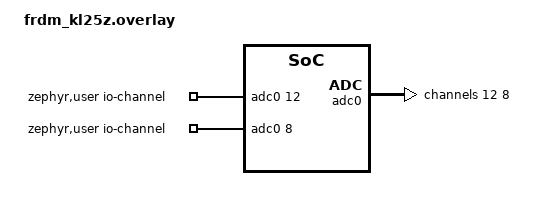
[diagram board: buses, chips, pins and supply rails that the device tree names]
&gpiod {
status = "okay";
};
/ {
    zephyr,user {
        /* Conecta o canal 12 (PTB2) e 8 (PTB0) do adc0 ao nó de usuário */
        io-channels = <&adc0 12>, <&adc0 8>;
    };
};

&adc0 {
    status = "okay";
    #address-cells = <1>;
    #size-cells = <0>;

    /* Configuração interna para o canal 12 (LDR Direita) */
    channel@c {
        reg = <12>; /* Reg 0 (0xc) indica o canal analógico interno */
        zephyr,gain = "ADC_GAIN_1";            /* Sem amplificação de ganho */
        zephyr,reference = "ADC_REF_INTERNAL";      /* Utiliza a referência interna de tensão do chip (VREF) */
        zephyr,acquisition-time = <ADC_ACQ_TIME_DEFAULT>;
        zephyr,resolution = <12>;               /* Define a amostragem em 12 bits (Valor lido de 0 a 4095) */
    };

    /* Configuração interna para o canal 8 (LDR Esquerda - Pino PTB0) */
    channel@8 {
        reg = <8>; /* Reg 8 (0x8) indica o canal analógico interno */
        zephyr,gain = "ADC_GAIN_1";
        zephyr,reference = "ADC_REF_INTERNAL";
        zephyr,acquisition-time = <ADC_ACQ_TIME_DEFAULT>;
        zephyr,resolution = <12>;
    };
};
